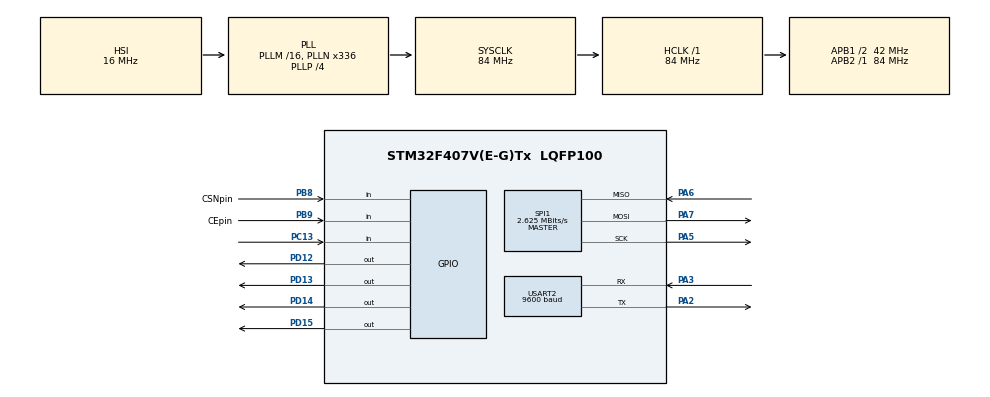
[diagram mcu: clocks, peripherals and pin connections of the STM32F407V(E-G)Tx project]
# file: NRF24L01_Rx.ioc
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Mcu.Family=STM32F4
PA6.Mode=Full_Duplex_Master
RCC.CortexFreq_Value=84000000
PA7.Mode=Full_Duplex_Master
PB9.GPIO_Label=CEpin
SPI1.VirtualType=VM_MASTER
RCC.APB1CLKDivider=RCC_HCLK_DIV2
USART2.BaudRate=9600
RCC.SYSCLKSource=RCC_SYSCLKSOURCE_PLLCLK
ProjectManager.StackSize=0x400
PD13.Signal=GPIO_Output
PA3.Mode=Asynchronous
PB8.GPIO_Label=CSNpin
ProjectManager.TargetToolchain=STM32CubeIDE
SPI1.Direction=SPI_DIRECTION_2LINES
RCC.HCLKFreq_Value=84000000
RCC.APB2TimFreq_Value=84000000
SPI1.CalculateBaudRate=2.625 MBits/s
RCC.LSE_VALUE=32768
RCC.AHBFreq_Value=84000000
PA5.Signal=SPI1_SCK
RCC.HSE_VALUE=25000000
board=custom
PC13-ANTI_TAMP.Signal=GPIO_Input
RCC.VCOOutputFreq_Value=336000000
RCC.APB2Freq_Value=84000000
SPI1.Mode=SPI_MODE_MASTER
Mcu.Name=STM32F407V(E-G)Tx
PA2.Signal=USART2_TX
PD14.Signal=GPIO_Output
RCC.48MHZClocksFreq_Value=84000000
RCC.SYSCLKFreq_VALUE=84000000
Mcu.Package=LQFP100
PB9.Signal=GPIO_Input
PA6.Signal=SPI1_MISO
USART2.VirtualMode=VM_ASYNC
PD12.Signal=GPIO_Output
ProjectManager.HeapSize=0x200
RCC.HSI_VALUE=16000000
RCC.PLLP=RCC_PLLP_DIV4
NVIC.PriorityGroup=NVIC_PRIORITYGROUP_4
RCC.PLLN=336
RCC.APB1TimFreq_Value=84000000
PB8.Signal=GPIO_Input
PA2.Mode=Asynchronous
RCC.APB1Freq_Value=42000000
SPI1.BaudRatePrescaler=SPI_BAUDRATEPRESCALER_32
PD15.Signal=GPIO_Output
PA3.Signal=USART2_RX
PA5.Mode=Full_Duplex_Master
PA7.Signal=SPI1_MOSI

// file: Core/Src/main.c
/* USER CODE BEGIN Header */
/**
  ******************************************************************************
  * @file           : main.c
  * @brief          : Main program body
  ******************************************************************************
  * @attention
  *
  * <h2><center>&copy; Copyright (c) 2021 STMicroelectronics.
  * All rights reserved.</center></h2>
  *
  * This software component is licensed by ST under BSD 3-Clause license,
  * the "License"; You may not use this file except in compliance with the
  * License. You may obtain a copy of the License at:
  *                        opensource.org/licenses/BSD-3-Clause
  *
  ******************************************************************************
  */
/* USER CODE END Header */
#include "main.h"
#include "MY_NRF24.h"

SPI_HandleTypeDef hspi1;

UART_HandleTypeDef huart2;

void SystemClock_Config(void);
static void MX_GPIO_Init(void);
static void MX_SPI1_Init(void);
static void MX_USART2_UART_Init(void);

/* USER CODE BEGIN 0 */
uint64_t RxpipeAddrs=0x11223344AA;
char myRxData[50];
char myAckPayload[32] = "Ack by STMF7!";
/* USER CODE END 0 */

int main(void)
{

  /* MCU Configuration--------------------------------------------------------*/

  /* Reset of all peripherals, Initializes the Flash interface and the Systick. */
  HAL_Init();

  /* Configure the system clock */
  SystemClock_Config();

  /* Initialize all configured peripherals */
  MX_GPIO_Init();
  MX_SPI1_Init();
  MX_USART2_UART_Init();
  /* USER CODE BEGIN 2 */
  NRF24_begin(CEpin_GPIO_Port, CSNpin_Pin, CEpin_Pin,hspi1);
  nrf24_DebugUART_Init(huart2);

  printRadioSettings();
  //**** TRANSMIT - NO ACK ****//
	NRF24_setAutoAck(true);
	NRF24_setChannel(52);
	NRF24_setPayloadSize(32);
	NRF24_openReadingPipe(1, RxpipeAddrs);
	NRF24_enableDynamicPayloads();
	NRF24_enableAckPayload();

	NRF24_startListening();
  /* USER CODE END 2 */

  /* Infinite loop */
  while (1)
  {
	  if(NRF24_available())
	  {
		    HAL_GPIO_TogglePin(GPIOD, GPIO_PIN_12);
			NRF24_read(myRxData, 32);
			//NRF24_writeAckPayload(1, myAckPayload, 32);
			myRxData[32] = '\r'; myRxData[32+1] = '\n';
			HAL_UART_Transmit(&huart2, (uint8_t *)myRxData, 32+2, 10);
	  }
	 // HAL_Delay(1000);
  }
}

void SystemClock_Config(void)
{
  RCC_OscInitTypeDef RCC_OscInitStruct = {0};
  RCC_ClkInitTypeDef RCC_ClkInitStruct = {0};

  /** Configure the main internal regulator output voltage
  */
  __HAL_RCC_PWR_CLK_ENABLE();
  __HAL_PWR_VOLTAGESCALING_CONFIG(PWR_REGULATOR_VOLTAGE_SCALE1);
  /** Initializes the RCC Oscillators according to the specified parameters
  * in the RCC_OscInitTypeDef structure.
  */
  RCC_OscInitStruct.OscillatorType = RCC_OSCILLATORTYPE_HSI;
  RCC_OscInitStruct.HSIState = RCC_HSI_ON;
  RCC_OscInitStruct.HSICalibrationValue = RCC_HSICALIBRATION_DEFAULT;
  RCC_OscInitStruct.PLL.PLLState = RCC_PLL_ON;
  RCC_OscInitStruct.PLL.PLLSource = RCC_PLLSOURCE_HSI;
  RCC_OscInitStruct.PLL.PLLM = 16;
  RCC_OscInitStruct.PLL.PLLN = 336;
  RCC_OscInitStruct.PLL.PLLP = RCC_PLLP_DIV4;
  RCC_OscInitStruct.PLL.PLLQ = 4;
  if (HAL_RCC_OscConfig(&RCC_OscInitStruct) != HAL_OK)
  {
    Error_Handler();
  }
  /** Initializes the CPU, AHB and APB buses clocks
  */
  RCC_ClkInitStruct.ClockType = RCC_CLOCKTYPE_HCLK|RCC_CLOCKTYPE_SYSCLK
                              |RCC_CLOCKTYPE_PCLK1|RCC_CLOCKTYPE_PCLK2;
  RCC_ClkInitStruct.SYSCLKSource = RCC_SYSCLKSOURCE_PLLCLK;
  RCC_ClkInitStruct.AHBCLKDivider = RCC_SYSCLK_DIV1;
  RCC_ClkInitStruct.APB1CLKDivider = RCC_HCLK_DIV2;
  RCC_ClkInitStruct.APB2CLKDivider = RCC_HCLK_DIV1;

  if (HAL_RCC_ClockConfig(&RCC_ClkInitStruct, FLASH_LATENCY_2) != HAL_OK)
  {
    Error_Handler();
  }
}

static void MX_SPI1_Init(void)
{

  /* SPI1 parameter configuration*/
  hspi1.Instance = SPI1;
  hspi1.Init.Mode = SPI_MODE_MASTER;
  hspi1.Init.Direction = SPI_DIRECTION_2LINES;
  hspi1.Init.DataSize = SPI_DATASIZE_8BIT;
  hspi1.Init.CLKPolarity = SPI_POLARITY_LOW;
  hspi1.Init.CLKPhase = SPI_PHASE_1EDGE;
  hspi1.Init.NSS = SPI_NSS_SOFT;
  hspi1.Init.BaudRatePrescaler = SPI_BAUDRATEPRESCALER_32;
  hspi1.Init.FirstBit = SPI_FIRSTBIT_MSB;
  hspi1.Init.TIMode = SPI_TIMODE_DISABLE;
  hspi1.Init.CRCCalculation = SPI_CRCCALCULATION_DISABLE;
  hspi1.Init.CRCPolynomial = 10;
  if (HAL_SPI_Init(&hspi1) != HAL_OK)
  {
    Error_Handler();
  }

}

static void MX_USART2_UART_Init(void)
{

  huart2.Instance = USART2;
  huart2.Init.BaudRate = 9600;
  huart2.Init.WordLength = UART_WORDLENGTH_8B;
  huart2.Init.StopBits = UART_STOPBITS_1;
  huart2.Init.Parity = UART_PARITY_NONE;
  huart2.Init.Mode = UART_MODE_TX_RX;
  huart2.Init.HwFlowCtl = UART_HWCONTROL_NONE;
  huart2.Init.OverSampling = UART_OVERSAMPLING_16;
  if (HAL_UART_Init(&huart2) != HAL_OK)
  {
    Error_Handler();
  }

}

static void MX_GPIO_Init(void)
{
  GPIO_InitTypeDef GPIO_InitStruct = {0};

  /* GPIO Ports Clock Enable */
  __HAL_RCC_GPIOC_CLK_ENABLE();
  __HAL_RCC_GPIOA_CLK_ENABLE();
  __HAL_RCC_GPIOD_CLK_ENABLE();
  __HAL_RCC_GPIOB_CLK_ENABLE();

  /*Configure GPIO pin Output Level */
  HAL_GPIO_WritePin(GPIOD, GPIO_PIN_12|GPIO_PIN_13|GPIO_PIN_14|GPIO_PIN_15, GPIO_PIN_RESET);

  /*Configure GPIO pin : PC13 */
  GPIO_InitStruct.Pin = GPIO_PIN_13;
  GPIO_InitStruct.Mode = GPIO_MODE_INPUT;
  GPIO_InitStruct.Pull = GPIO_NOPULL;
  HAL_GPIO_Init(GPIOC, &GPIO_InitStruct);

  /*Configure GPIO pins : PD12 PD13 PD14 PD15 */
  GPIO_InitStruct.Pin = GPIO_PIN_12|GPIO_PIN_13|GPIO_PIN_14|GPIO_PIN_15;
  GPIO_InitStruct.Mode = GPIO_MODE_OUTPUT_PP;
  GPIO_InitStruct.Pull = GPIO_NOPULL;
  GPIO_InitStruct.Speed = GPIO_SPEED_FREQ_LOW;
  HAL_GPIO_Init(GPIOD, &GPIO_InitStruct);

  /*Configure GPIO pins : CSNpin_Pin CEpin_Pin */
  GPIO_InitStruct.Pin = CSNpin_Pin|CEpin_Pin;
  GPIO_InitStruct.Mode = GPIO_MODE_INPUT;
  GPIO_InitStruct.Pull = GPIO_NOPULL;
  HAL_GPIO_Init(GPIOB, &GPIO_InitStruct);

}

void Error_Handler(void)
{
  __disable_irq();
  while (1)
  {
  }
}

/************************ (C) COPYRIGHT STMicroelectronics *****END OF FILE****/
